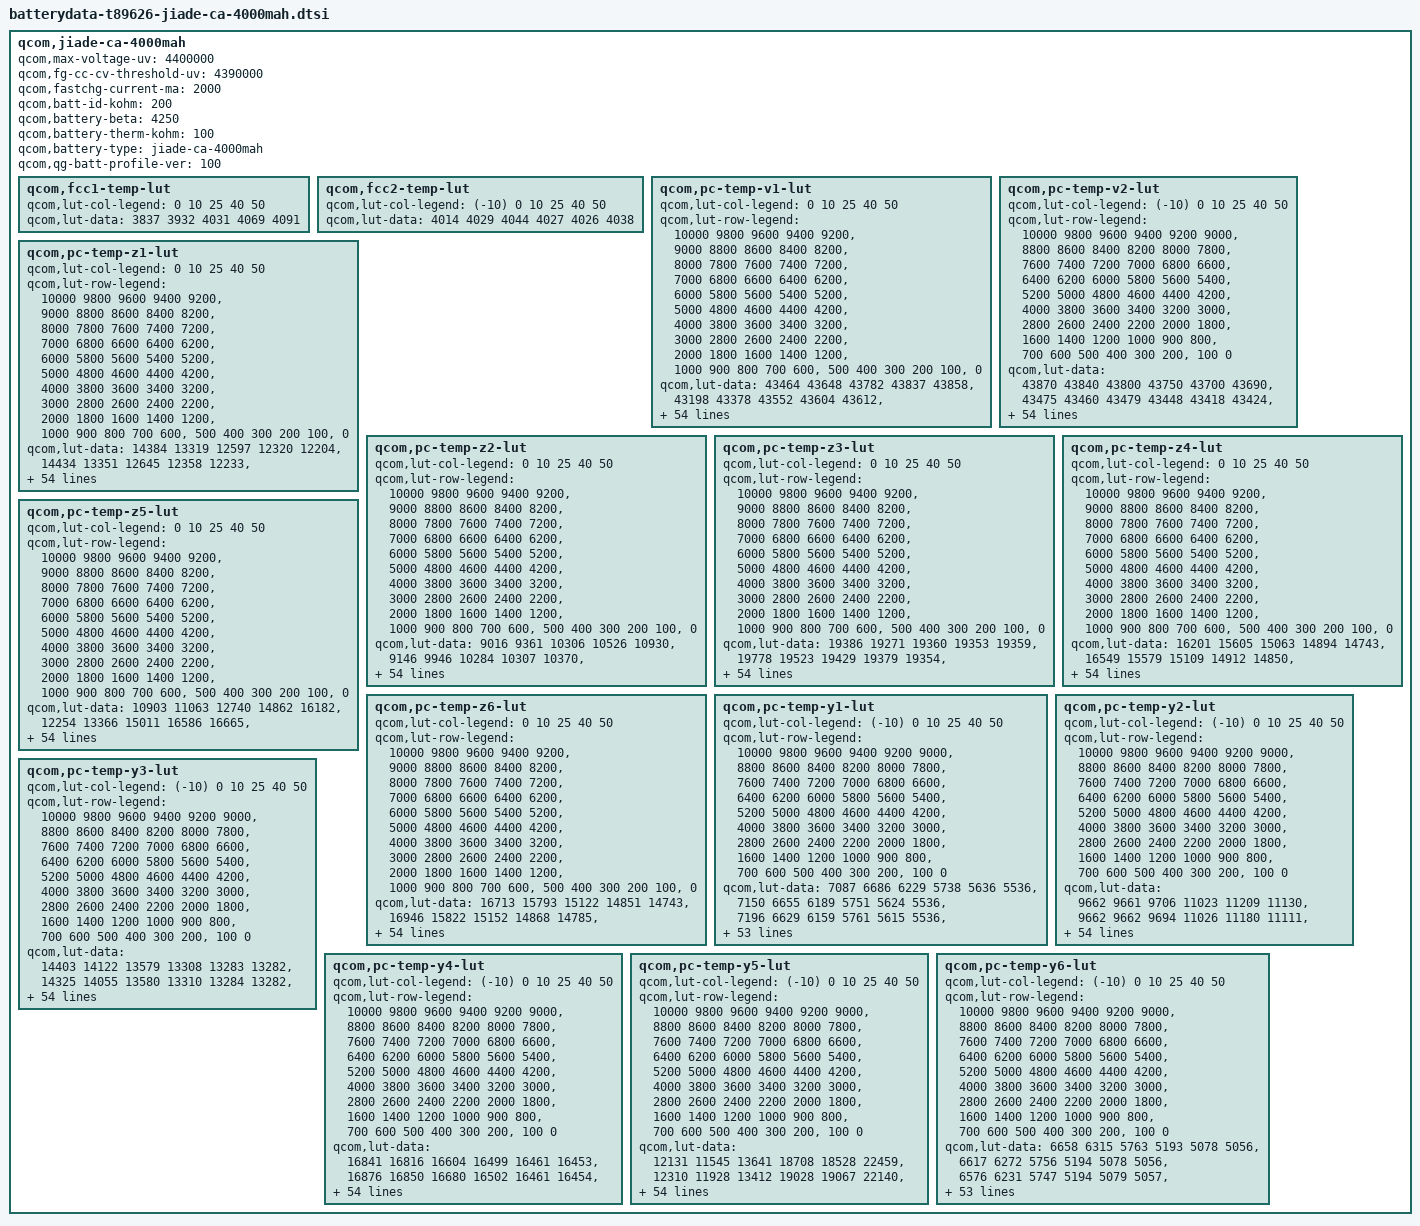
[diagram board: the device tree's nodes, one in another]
qcom,jiade-ca-4000mah {
    /* 3763683_Wingtech_T89626_JD_4000mAh_FG_averaged_MasterSlave_Jan8th2019 */
    qcom,max-voltage-uv = <4400000>;
    qcom,fg-cc-cv-threshold-uv = <4390000>;
    qcom,fastchg-current-ma = <2000>;
    qcom,batt-id-kohm = <200>;
    qcom,battery-beta = <4250>;
    qcom,battery-therm-kohm = <100>;
    qcom,battery-type = "jiade-ca-4000mah";
    qcom,qg-batt-profile-ver = <100>;

	qcom,fcc1-temp-lut {
		qcom,lut-col-legend = <0 10 25 40 50>;
		qcom,lut-data = <3837 3932 4031 4069 4091>;
	};

	qcom,fcc2-temp-lut {
		qcom,lut-col-legend = <(-10) 0 10 25 40 50>;
		qcom,lut-data = <4014 4029 4044 4027 4026 4038>;
	};

	qcom,pc-temp-v1-lut {
		qcom,lut-col-legend = <0 10 25 40 50>;
		qcom,lut-row-legend = <10000 9800 9600 9400 9200>,
			<9000 8800 8600 8400 8200>,
			<8000 7800 7600 7400 7200>,
			<7000 6800 6600 6400 6200>,
			<6000 5800 5600 5400 5200>,
			<5000 4800 4600 4400 4200>,
			<4000 3800 3600 3400 3200>,
			<3000 2800 2600 2400 2200>,
			<2000 1800 1600 1400 1200>,
			<1000 900 800 700 600>,
			<500 400 300 200 100>,
			<0>;
		qcom,lut-data = <43464 43648 43782 43837 43858>,
			<43198 43378 43552 43604 43612>,
			<42939 43121 43306 43371 43382>,
			<42690 42879 43062 43137 43152>,
			<42454 42645 42824 42903 42921>,
			<42227 42410 42588 42667 42686>,
			<42009 42179 42355 42433 42453>,
			<41801 41956 42123 42200 42222>,
			<41602 41740 41895 41971 41993>,
			<41409 41532 41670 41745 41767>,
			<41227 41338 41451 41522 41542>,
			<41032 41156 41247 41303 41322>,
			<40806 40960 41056 41087 41104>,
			<40566 40728 40857 40878 40892>,
			<40338 40486 40633 40674 40687>,
			<40111 40268 40413 40476 40490>,
			<39913 40062 40221 40289 40300>,
			<39762 39885 40045 40113 40118>,
			<39636 39745 39882 39944 39943>,
			<39513 39620 39743 39784 39780>,
			<39389 39487 39596 39627 39625>,
			<39271 39347 39384 39434 39440>,
			<39157 39202 39118 39172 39190>,
			<39048 39045 38916 38943 38961>,
			<38944 38883 38775 38805 38817>,
			<38846 38731 38663 38698 38702>,
			<38752 38579 38572 38594 38592>,
			<38666 38458 38497 38494 38485>,
			<38584 38387 38425 38404 38388>,
			<38509 38334 38355 38321 38303>,
			<38439 38287 38291 38248 38227>,
			<38373 38244 38230 38179 38156>,
			<38317 38205 38175 38118 38091>,
			<38269 38168 38125 38060 38029>,
			<38226 38135 38083 38011 37972>,
			<38183 38105 38043 37963 37916>,
			<38140 38082 38003 37911 37856>,
			<38093 38054 37962 37856 37794>,
			<38035 38006 37902 37790 37720>,
			<37966 37925 37809 37703 37629>,
			<37881 37829 37701 37601 37526>,
			<37765 37711 37588 37492 37414>,
			<37633 37575 37460 37367 37288>,
			<37482 37418 37302 37217 37131>,
			<37337 37275 37163 37076 36998>,
			<37231 37171 37068 36981 36917>,
			<37194 37135 37046 36951 36887>,
			<37164 37111 37026 36931 36867>,
			<37136 37085 37005 36912 36849>,
			<37082 37038 36958 36865 36782>,
			<36879 36812 36709 36637 36504>,
			<36440 36376 36276 36200 36065>,
			<35871 35803 35700 35612 35490>,
			<35093 35019 34918 34805 34705>,
			<33855 33776 33672 33521 33485>,
			<30000 30000 30000 30000 30000>;
	};

	qcom,pc-temp-v2-lut {
		qcom,lut-col-legend = <(-10) 0 10 25 40 50>;
		qcom,lut-row-legend = <10000 9800 9600 9400 9200 9000>,
			<8800 8600 8400 8200 8000 7800>,
			<7600 7400 7200 7000 6800 6600>,
			<6400 6200 6000 5800 5600 5400>,
			<5200 5000 4800 4600 4400 4200>,
			<4000 3800 3600 3400 3200 3000>,
			<2800 2600 2400 2200 2000 1800>,
			<1600 1400 1200 1000 900 800>,
			<700 600 500 400 300 200>,
			<100 0>;
		qcom,lut-data = <43870 43840 43800 43750 43700 43690>,
			<43475 43460 43479 43448 43418 43424>,
			<43116 43115 43174 43164 43151 43168>,
			<42800 42810 42890 42903 42899 42922>,
			<42520 42540 42622 42662 42663 42687>,
			<42258 42284 42367 42426 42431 42455>,
			<42007 42033 42124 42193 42199 42223>,
			<41769 41792 41890 41962 41970 41993>,
			<41539 41560 41661 41735 41743 41766>,
			<41314 41332 41436 41512 41519 41541>,
			<41116 41139 41223 41292 41298 41319>,
			<40973 41008 41031 41077 41082 41103>,
			<40833 40882 40842 40866 40871 40890>,
			<40579 40647 40631 40659 40668 40684>,
			<40136 40257 40401 40454 40470 40482>,
			<39769 39924 40171 40257 40280 40289>,
			<39558 39703 39942 40067 40097 40105>,
			<39390 39516 39717 39886 39921 39927>,
			<39223 39333 39504 39724 39752 39757>,
			<39066 39162 39298 39580 39594 39595>,
			<38918 38998 39104 39410 39415 39413>,
			<38775 38837 38917 39168 39182 39185>,
			<38645 38685 38746 38917 38945 38958>,
			<38533 38552 38596 38739 38768 38783>,
			<38436 38432 38460 38595 38621 38632>,
			<38349 38329 38346 38471 38495 38503>,
			<38272 38244 38248 38362 38385 38392>,
			<38202 38171 38165 38264 38287 38293>,
			<38133 38102 38096 38174 38197 38200>,
			<38066 38039 38036 38091 38114 38115>,
			<38005 37982 37980 38016 38039 38038>,
			<37947 37929 37928 37945 37973 37970>,
			<37894 37878 37878 37882 37911 37904>,
			<37847 37827 37829 37826 37844 37835>,
			<37806 37777 37783 37777 37776 37764>,
			<37764 37724 37734 37726 37700 37679>,
			<37721 37670 37684 37674 37611 37569>,
			<37676 37613 37628 37616 37520 37460>,
			<37615 37547 37563 37545 37439 37372>,
			<37538 37475 37490 37461 37363 37292>,
			<37450 37391 37407 37372 37280 37209>,
			<37344 37286 37306 37277 37189 37124>,
			<37224 37182 37188 37165 37083 37017>,
			<37085 37088 37051 37029 36953 36882>,
			<36964 37004 36926 36901 36840 36775>,
			<36898 36921 36840 36836 36789 36736>,
			<36875 36881 36813 36814 36775 36726>,
			<36854 36828 36777 36792 36758 36708>,
			<36819 36752 36732 36762 36727 36671>,
			<36736 36618 36628 36682 36637 36547>,
			<36478 36362 36384 36423 36347 36179>,
			<35992 35942 35926 35951 35860 35668>,
			<35349 35342 35285 35331 35230 35001>,
			<34449 34469 34375 34469 34378 34072>,
			<33161 33014 32955 33187 33121 32730>,
			<27680 28140 27790 27698 27500 28428>;
	};

	qcom,pc-temp-z1-lut {
		qcom,lut-col-legend = <0 10 25 40 50>;
		qcom,lut-row-legend = <10000 9800 9600 9400 9200>,
			<9000 8800 8600 8400 8200>,
			<8000 7800 7600 7400 7200>,
			<7000 6800 6600 6400 6200>,
			<6000 5800 5600 5400 5200>,
			<5000 4800 4600 4400 4200>,
			<4000 3800 3600 3400 3200>,
			<3000 2800 2600 2400 2200>,
			<2000 1800 1600 1400 1200>,
			<1000 900 800 700 600>,
			<500 400 300 200 100>,
			<0>;
		qcom,lut-data = <14384 13319 12597 12320 12204>,
			<14434 13351 12645 12358 12233>,
			<14430 13359 12659 12349 12233>,
			<14424 13352 12664 12336 12225>,
			<14416 13344 12662 12328 12216>,
			<14404 13341 12658 12321 12205>,
			<14386 13340 12649 12318 12199>,
			<14347 13340 12631 12320 12198>,
			<14314 13348 12622 12321 12197>,
			<14312 13358 12621 12320 12197>,
			<14315 13356 12621 12316 12196>,
			<14317 13347 12622 12313 12194>,
			<14271 13337 12627 12310 12193>,
			<14204 13325 12628 12308 12193>,
			<14190 13314 12624 12310 12193>,
			<14196 13314 12618 12316 12193>,
			<14201 13317 12622 12317 12193>,
			<14180 13323 12634 12315 12194>,
			<14132 13335 12639 12312 12195>,
			<14109 13353 12633 12313 12197>,
			<14106 13365 12627 12315 12199>,
			<14104 13375 12628 12317 12202>,
			<14098 13379 12631 12318 12205>,
			<14088 13372 12634 12320 12207>,
			<14083 13361 12636 12324 12209>,
			<14083 13361 12638 12330 12209>,
			<14086 13383 12646 12333 12211>,
			<14090 13400 12658 12335 12215>,
			<14100 13395 12663 12337 12220>,
			<14113 13383 12663 12344 12223>,
			<14127 13380 12664 12352 12227>,
			<14142 13387 12668 12354 12231>,
			<14164 13398 12677 12353 12238>,
			<14211 13415 12685 12353 12245>,
			<14253 13438 12695 12356 12250>,
			<14249 13445 12700 12362 12255>,
			<14217 13436 12695 12367 12260>,
			<14197 13426 12685 12375 12263>,
			<14232 13426 12685 12379 12267>,
			<14287 13431 12700 12380 12270>,
			<14298 13437 12713 12381 12273>,
			<14277 13441 12716 12390 12278>,
			<14275 13451 12717 12406 12285>,
			<14318 13501 12706 12407 12291>,
			<14288 13493 12703 12406 12291>,
			<14285 13452 12720 12395 12291>,
			<14343 13484 12702 12395 12290>,
			<14283 13468 12700 12408 12292>,
			<14233 13469 12713 12401 12292>,
			<14248 13494 12717 12401 12305>,
			<14252 13473 12735 12414 12314>,
			<14275 13527 12754 12417 12314>,
			<14301 13551 12771 12428 12326>,
			<14379 13606 12782 12458 12339>,
			<14379 13606 12782 12458 12339>,
			<14379 13606 12782 12458 12339>;
	};

	qcom,pc-temp-z2-lut {
		qcom,lut-col-legend = <0 10 25 40 50>;
		qcom,lut-row-legend = <10000 9800 9600 9400 9200>,
			<9000 8800 8600 8400 8200>,
			<8000 7800 7600 7400 7200>,
			<7000 6800 6600 6400 6200>,
			<6000 5800 5600 5400 5200>,
			<5000 4800 4600 4400 4200>,
			<4000 3800 3600 3400 3200>,
			<3000 2800 2600 2400 2200>,
			<2000 1800 1600 1400 1200>,
			<1000 900 800 700 600>,
			<500 400 300 200 100>,
			<0>;
		qcom,lut-data = <9016 9361 10306 10526 10930>,
			<9146 9946 10284 10307 10370>,
			<9628 10127 10357 10367 10373>,
			<9993 10126 10396 10454 10411>,
			<10014 10123 10387 10460 10419>,
			<10021 10114 10368 10425 10397>,
			<10029 10093 10349 10401 10371>,
			<10042 10079 10326 10394 10355>,
			<10051 10071 10310 10389 10339>,
			<10049 10067 10303 10382 10313>,
			<10038 10069 10298 10373 10268>,
			<10025 10077 10302 10370 10247>,
			<10004 10081 10318 10375 10262>,
			<9984 10075 10332 10385 10282>,
			<9980 10067 10343 10400 10284>,
			<9981 10070 10352 10420 10282>,
			<9983 10091 10360 10425 10281>,
			<9994 10120 10365 10412 10298>,
			<10023 10175 10375 10399 10321>,
			<10053 10233 10404 10403 10335>,
			<10094 10241 10429 10414 10346>,
			<10127 10228 10421 10430 10365>,
			<10078 10219 10393 10457 10409>,
			<9885 10222 10379 10474 10441>,
			<9763 10229 10375 10462 10419>,
			<9751 10230 10373 10438 10375>,
			<9745 10225 10374 10429 10365>,
			<9735 10220 10376 10427 10370>,
			<9721 10226 10376 10423 10373>,
			<9712 10239 10370 10392 10332>,
			<9712 10250 10365 10352 10264>,
			<9714 10256 10369 10346 10240>,
			<9707 10262 10382 10351 10229>,
			<9571 10275 10390 10360 10226>,
			<9416 10291 10394 10376 10248>,
			<9410 10294 10399 10398 10289>,
			<9457 10246 10407 10419 10332>,
			<9485 10197 10419 10440 10385>,
			<9484 10214 10435 10461 10408>,
			<9481 10296 10461 10488 10411>,
			<9480 10402 10477 10507 10414>,
			<9480 10595 10474 10490 10419>,
			<9477 10691 10469 10450 10427>,
			<9455 10388 10472 10464 10448>,
			<9419 10928 10516 10489 10449>,
			<9411 11215 10559 10503 10436>,
			<9418 10701 10583 10502 10440>,
			<9408 11307 10621 10516 10435>,
			<9411 10609 10804 10507 10487>,
			<9403 10768 11191 10621 10552>,
			<9375 11064 10733 10554 10367>,
			<9360 10423 10751 10462 10268>,
			<9348 10282 10649 10381 10249>,
			<9309 9997 10611 10321 10194>,
			<9309 9997 10611 10321 10194>,
			<9309 9997 10611 10321 10194>;
	};

	qcom,pc-temp-z3-lut {
		qcom,lut-col-legend = <0 10 25 40 50>;
		qcom,lut-row-legend = <10000 9800 9600 9400 9200>,
			<9000 8800 8600 8400 8200>,
			<8000 7800 7600 7400 7200>,
			<7000 6800 6600 6400 6200>,
			<6000 5800 5600 5400 5200>,
			<5000 4800 4600 4400 4200>,
			<4000 3800 3600 3400 3200>,
			<3000 2800 2600 2400 2200>,
			<2000 1800 1600 1400 1200>,
			<1000 900 800 700 600>,
			<500 400 300 200 100>,
			<0>;
		qcom,lut-data = <19386 19271 19360 19353 19359>,
			<19778 19523 19429 19379 19354>,
			<19843 19625 19467 19392 19367>,
			<19865 19650 19482 19399 19376>,
			<19865 19663 19487 19405 19382>,
			<19864 19670 19489 19409 19387>,
			<19861 19675 19490 19411 19390>,
			<19839 19677 19490 19413 19390>,
			<19814 19669 19491 19413 19389>,
			<19804 19657 19491 19412 19387>,
			<19797 19641 19490 19405 19381>,
			<19795 19619 19487 19401 19377>,
			<19803 19610 19476 19399 19375>,
			<19816 19615 19468 19397 19373>,
			<19816 19622 19464 19396 19371>,
			<19802 19622 19461 19394 19368>,
			<19779 19616 19458 19392 19365>,
			<19743 19608 19455 19388 19364>,
			<19692 19574 19452 19384 19363>,
			<19648 19532 19445 19381 19360>,
			<19615 19528 19439 19379 19354>,
			<19582 19548 19445 19380 19353>,
			<19536 19571 19462 19386 19360>,
			<19475 19592 19468 19392 19365>,
			<19443 19610 19466 19387 19364>,
			<19439 19614 19462 19380 19363>,
			<19436 19614 19460 19381 19365>,
			<19434 19614 19458 19397 19385>,
			<19431 19611 19457 19408 19399>,
			<19428 19603 19458 19407 19395>,
			<19427 19595 19458 19405 19388>,
			<19427 19587 19460 19403 19383>,
			<19422 19577 19462 19400 19378>,
			<19359 19569 19462 19396 19373>,
			<19286 19561 19459 19391 19368>,
			<19274 19539 19455 19386 19363>,
			<19272 19406 19450 19383 19360>,
			<19271 19274 19445 19382 19358>,
			<19271 19262 19444 19380 19357>,
			<19271 19262 19445 19379 19357>,
			<19271 19261 19446 19378 19357>,
			<19270 19260 19442 19374 19355>,
			<19270 19260 19436 19369 19353>,
			<19271 19261 19435 19369 19358>,
			<19272 19259 19424 19366 19358>,
			<19272 19258 19413 19356 19342>,
			<19272 19260 19388 19355 19340>,
			<19273 19258 19357 19351 19337>,
			<19272 19260 19334 19353 19327>,
			<19272 19259 19268 19337 19326>,
			<19274 19259 19342 19348 19351>,
			<19275 19260 19334 19358 19356>,
			<19275 19261 19338 19362 19356>,
			<19278 19263 19272 19361 19356>,
			<19278 19263 19272 19361 19356>,
			<19278 19263 19272 19361 19356>;
	};

	qcom,pc-temp-z4-lut {
		qcom,lut-col-legend = <0 10 25 40 50>;
		qcom,lut-row-legend = <10000 9800 9600 9400 9200>,
			<9000 8800 8600 8400 8200>,
			<8000 7800 7600 7400 7200>,
			<7000 6800 6600 6400 6200>,
			<6000 5800 5600 5400 5200>,
			<5000 4800 4600 4400 4200>,
			<4000 3800 3600 3400 3200>,
			<3000 2800 2600 2400 2200>,
			<2000 1800 1600 1400 1200>,
			<1000 900 800 700 600>,
			<500 400 300 200 100>,
			<0>;
		qcom,lut-data = <16201 15605 15063 14894 14743>,
			<16549 15579 15109 14912 14850>,
			<16347 15519 15055 14895 14850>,
			<16113 15384 14993 14862 14830>,
			<15948 15233 14931 14833 14811>,
			<15797 15132 14872 14804 14790>,
			<15666 15050 14829 14778 14770>,
			<15549 14987 14796 14756 14753>,
			<15448 14937 14769 14737 14737>,
			<15366 14899 14745 14722 14725>,
			<15297 14874 14726 14709 14715>,
			<15237 14856 14712 14700 14707>,
			<15181 14837 14700 14693 14700>,
			<15134 14811 14695 14687 14694>,
			<15108 14785 14694 14681 14690>,
			<15090 14767 14694 14676 14686>,
			<15081 14751 14690 14672 14682>,
			<15085 14744 14682 14667 14676>,
			<15097 14758 14675 14664 14672>,
			<15109 14778 14670 14662 14670>,
			<15119 14775 14667 14660 14668>,
			<15131 14742 14693 14668 14673>,
			<15158 14719 14763 14739 14736>,
			<15208 14719 14792 14795 14789>,
			<15234 14721 14795 14793 14787>,
			<15225 14728 14797 14785 14775>,
			<15206 14759 14787 14771 14759>,
			<15190 14783 14762 14739 14726>,
			<15178 14777 14741 14712 14700>,
			<15165 14760 14725 14698 14691>,
			<15148 14745 14711 14688 14685>,
			<15130 14734 14699 14681 14679>,
			<15126 14725 14689 14675 14673>,
			<15174 14718 14683 14672 14670>,
			<15229 14713 14680 14671 14669>,
			<15231 14718 14678 14670 14668>,
			<15212 14849 14676 14670 14668>,
			<15192 14987 14674 14670 14670>,
			<15177 14997 14674 14670 14671>,
			<15162 14992 14677 14674 14675>,
			<15150 14987 14678 14677 14679>,
			<15141 14985 14676 14676 14676>,
			<15129 14981 14672 14673 14669>,
			<15108 14974 14670 14673 14669>,
			<15014 14931 14665 14672 14666>,
			<14990 14902 14652 14658 14655>,
			<14986 14898 14669 14652 14650>,
			<14979 14895 14696 14644 14639>,
			<14978 14888 14718 14631 14633>,
			<14975 14886 14790 14646 14634>,
			<14976 14896 14717 14651 14637>,
			<14999 14910 14733 14651 14641>,
			<15017 14919 14733 14651 14646>,
			<15040 14933 14811 14657 14651>,
			<15040 14933 14811 14657 14651>,
			<15040 14933 14811 14657 14651>;
	};

	qcom,pc-temp-z5-lut {
		qcom,lut-col-legend = <0 10 25 40 50>;
		qcom,lut-row-legend = <10000 9800 9600 9400 9200>,
			<9000 8800 8600 8400 8200>,
			<8000 7800 7600 7400 7200>,
			<7000 6800 6600 6400 6200>,
			<6000 5800 5600 5400 5200>,
			<5000 4800 4600 4400 4200>,
			<4000 3800 3600 3400 3200>,
			<3000 2800 2600 2400 2200>,
			<2000 1800 1600 1400 1200>,
			<1000 900 800 700 600>,
			<500 400 300 200 100>,
			<0>;
		qcom,lut-data = <10903 11063 12740 14862 16182>,
			<12254 13366 15011 16586 16665>,
			<13107 14624 16692 17706 17766>,
			<13710 15179 17896 18525 18717>,
			<14166 15617 18660 19318 19604>,
			<14518 16235 19295 20034 20460>,
			<14656 16915 20080 20809 21174>,
			<14688 17299 20958 21839 21745>,
			<14715 17487 22004 22809 22199>,
			<14796 17591 23691 23316 22438>,
			<14971 17491 25185 23623 22555>,
			<15193 17128 25497 24081 22744>,
			<15569 16959 25583 25009 23497>,
			<15954 18067 25751 26208 24525>,
			<16020 19895 26446 27694 25145>,
			<15913 21321 27323 29403 25569>,
			<15724 22703 27929 29917 26270>,
			<15174 23326 28447 29778 28395>,
			<14170 20793 28594 29651 30280>,
			<13457 17020 28211 30147 30021>,
			<13059 16647 27811 31236 28867>,
			<12725 19358 32560 31556 27884>,
			<12322 23628 45391 31562 27252>,
			<11867 33851 49746 31564 26409>,
			<11655 46832 41347 27758 23498>,
			<11671 49688 31957 20924 19217>,
			<11702 49436 28547 19756 18824>,
			<11728 48955 26323 22128 23366>,
			<11750 46568 25822 24805 27209>,
			<11775 41636 26457 26749 28103>,
			<11819 37626 27640 28649 28703>,
			<11874 34496 30470 30975 29886>,
			<11875 31803 35269 33866 31880>,
			<11486 29832 38339 35343 33079>,
			<11045 28244 40362 35606 33419>,
			<10990 25563 41368 35738 33599>,
			<10991 18192 39720 35636 33499>,
			<10993 11670 36596 35112 32970>,
			<10999 11170 36136 34369 32193>,
			<11009 11194 38236 33138 30608>,
			<11021 11205 39837 31374 28708>,
			<11037 11202 36711 28456 26996>,
			<11062 11200 32577 25127 25694>,
			<11115 11225 32457 24796 28510>,
			<11375 11360 30696 24188 29055>,
			<11413 11406 29984 22500 21848>,
			<11394 11393 20320 22804 21689>,
			<11393 11366 15577 22615 22212>,
			<11372 11367 13776 25538 20860>,
			<11393 11385 11575 19439 19460>,
			<11420 11417 14294 19548 26141>,
			<11404 11341 13493 20711 25454>,
			<11317 11288 13508 20920 22670>,
			<11235 11193 11471 19385 20552>,
			<11235 11193 11471 19385 20552>,
			<11235 11193 11471 19385 20552>;
	};

	qcom,pc-temp-z6-lut {
		qcom,lut-col-legend = <0 10 25 40 50>;
		qcom,lut-row-legend = <10000 9800 9600 9400 9200>,
			<9000 8800 8600 8400 8200>,
			<8000 7800 7600 7400 7200>,
			<7000 6800 6600 6400 6200>,
			<6000 5800 5600 5400 5200>,
			<5000 4800 4600 4400 4200>,
			<4000 3800 3600 3400 3200>,
			<3000 2800 2600 2400 2200>,
			<2000 1800 1600 1400 1200>,
			<1000 900 800 700 600>,
			<500 400 300 200 100>,
			<0>;
		qcom,lut-data = <16713 15793 15122 14851 14743>,
			<16946 15822 15152 14868 14785>,
			<16821 15819 15129 14861 14788>,
			<16673 15738 15100 14848 14784>,
			<16566 15630 15064 14835 14779>,
			<16467 15560 15026 14821 14770>,
			<16370 15502 14998 14808 14762>,
			<16270 15452 14976 14798 14754>,
			<16181 15409 14957 14788 14746>,
			<16114 15372 14942 14778 14739>,
			<16061 15340 14929 14768 14731>,
			<16012 15312 14917 14761 14725>,
			<15964 15286 14905 14757 14720>,
			<15918 15258 14896 14753 14717>,
			<15877 15233 14889 14750 14713>,
			<15840 15218 14883 14746 14710>,
			<15809 15207 14879 14743 14707>,
			<15785 15199 14876 14739 14704>,
			<15765 15191 14873 14736 14702>,
			<15746 15185 14869 14734 14699>,
			<15729 15184 14867 14732 14696>,
			<15714 15186 14882 14736 14698>,
			<15698 15189 14923 14771 14728>,
			<15681 15197 14940 14799 14755>,
			<15668 15211 14941 14796 14754>,
			<15658 15225 14942 14791 14749>,
			<15651 15242 14938 14786 14745>,
			<15646 15252 14929 14781 14742>,
			<15644 15250 14922 14777 14738>,
			<15642 15242 14917 14773 14734>,
			<15638 15235 14914 14768 14728>,
			<15633 15229 14913 14765 14723>,
			<15631 15223 14912 14762 14719>,
			<15631 15218 14911 14759 14716>,
			<15631 15214 14910 14757 14713>,
			<15630 15211 14910 14756 14711>,
			<15627 15208 14910 14756 14711>,
			<15625 15206 14910 14756 14711>,
			<15628 15207 14912 14757 14712>,
			<15634 15209 14918 14760 14715>,
			<15635 15211 14923 14763 14718>,
			<15635 15216 14923 14762 14717>,
			<15636 15222 14922 14759 14714>,
			<15640 15227 14924 14760 14718>,
			<15609 15219 14921 14760 14717>,
			<15603 15209 14915 14750 14705>,
			<15600 15208 14910 14748 14701>,
			<15596 15209 14907 14743 14696>,
			<15596 15204 14907 14739 14689>,
			<15603 15211 14908 14739 14689>,
			<15613 15221 14919 14750 14706>,
			<15630 15237 14925 14757 14713>,
			<15654 15251 14933 14763 14718>,
			<15682 15272 14943 14770 14724>,
			<15682 15272 14943 14770 14724>,
			<15682 15272 14943 14770 14724>;
	};

	qcom,pc-temp-y1-lut {
		qcom,lut-col-legend = <(-10) 0 10 25 40 50>;
		qcom,lut-row-legend = <10000 9800 9600 9400 9200 9000>,
			<8800 8600 8400 8200 8000 7800>,
			<7600 7400 7200 7000 6800 6600>,
			<6400 6200 6000 5800 5600 5400>,
			<5200 5000 4800 4600 4400 4200>,
			<4000 3800 3600 3400 3200 3000>,
			<2800 2600 2400 2200 2000 1800>,
			<1600 1400 1200 1000 900 800>,
			<700 600 500 400 300 200>,
			<100 0>;
		qcom,lut-data = <7087 6686 6229 5738 5636 5536>,
			<7150 6655 6189 5751 5624 5536>,
			<7196 6629 6159 5761 5615 5536>,
			<7225 6609 6137 5768 5609 5536>,
			<7242 6596 6125 5773 5605 5536>,
			<7247 6592 6121 5775 5603 5536>,
			<7231 6599 6132 5771 5607 5535>,
			<7206 6610 6147 5767 5611 5533>,
			<7201 6608 6147 5767 5611 5531>,
			<7199 6589 6139 5770 5606 5530>,
			<7199 6578 6132 5772 5601 5529>,
			<7236 6593 6129 5769 5598 5527>,
			<7295 6616 6127 5766 5595 5526>,
			<7326 6626 6131 5767 5595 5524>,
			<7346 6633 6148 5775 5597 5521>,
			<7353 6635 6157 5783 5600 5519>,
			<7331 6625 6158 5789 5601 5519>,
			<7296 6612 6158 5794 5602 5518>,
			<7278 6614 6163 5792 5601 5518>,
			<7266 6627 6173 5784 5596 5517>,
			<7259 6632 6177 5780 5594 5517>,
			<7257 6623 6171 5783 5594 5518>,
			<7255 6613 6163 5786 5595 5520>,
			<7248 6615 6156 5786 5598 5520>,
			<7226 6627 6151 5784 5604 5521>,
			<7190 6636 6149 5783 5606 5522>,
			<7060 6639 6151 5786 5606 5523>,
			<6875 6643 6154 5790 5606 5525>,
			<6741 6649 6161 5790 5608 5527>,
			<6628 6659 6172 5789 5614 5530>,
			<6537 6663 6173 5789 5619 5533>,
			<6467 6662 6158 5797 5623 5536>,
			<6407 6660 6144 5806 5626 5539>,
			<6344 6655 6145 5807 5626 5542>,
			<6281 6643 6148 5806 5625 5547>,
			<6221 6630 6151 5806 5625 5548>,
			<6158 6613 6155 5806 5625 5548>,
			<6104 6599 6158 5806 5626 5548>,
			<6070 6597 6157 5804 5627 5550>,
			<6047 6595 6154 5798 5630 5554>,
			<6027 6597 6149 5796 5633 5556>,
			<6012 6619 6140 5798 5638 5557>,
			<5995 6628 6147 5798 5640 5560>,
			<5972 6620 6175 5793 5635 5567>,
			<5958 6614 6167 5804 5640 5569>,
			<5940 6679 6160 5813 5641 5573>,
			<5938 6691 6165 5809 5639 5571>,
			<5939 6682 6202 5813 5642 5569>,
			<5934 6660 6192 5806 5642 5569>,
			<5917 6662 6193 5804 5642 5567>,
			<5920 6696 6183 5824 5645 5574>,
			<5926 6714 6227 5838 5654 5583>,
			<5920 6759 6218 5828 5662 5584>,
			<5946 6797 6241 5841 5675 5596>,
			<5946 6797 6241 5841 5675 5596>,
			<5946 6797 6241 5841 5675 5596>;
	};

	qcom,pc-temp-y2-lut {
		qcom,lut-col-legend = <(-10) 0 10 25 40 50>;
		qcom,lut-row-legend = <10000 9800 9600 9400 9200 9000>,
			<8800 8600 8400 8200 8000 7800>,
			<7600 7400 7200 7000 6800 6600>,
			<6400 6200 6000 5800 5600 5400>,
			<5200 5000 4800 4600 4400 4200>,
			<4000 3800 3600 3400 3200 3000>,
			<2800 2600 2400 2200 2000 1800>,
			<1600 1400 1200 1000 900 800>,
			<700 600 500 400 300 200>,
			<100 0>;
		qcom,lut-data = <9662 9661 9706 11023 11209 11130>,
			<9662 9662 9694 11026 11180 11111>,
			<9662 9663 9688 11023 11149 11092>,
			<9662 9665 9688 11015 11119 11073>,
			<9662 9666 9694 11003 11094 11054>,
			<9663 9666 9705 10988 11077 11035>,
			<9663 9667 9843 10967 11068 11016>,
			<9664 9667 10064 10943 11061 10997>,
			<9664 9668 10204 10928 11047 10978>,
			<9664 9668 10313 10916 11019 10958>,
			<9664 9669 10376 10904 11000 10949>,
			<9664 9670 10398 10883 10994 10953>,
			<9664 9671 10417 10864 10990 10957>,
			<9664 9670 10476 10870 10986 10953>,
			<9664 9669 10590 10910 10983 10935>,
			<9664 9668 10628 10952 10982 10924>,
			<9664 9668 10256 10984 11011 10921>,
			<9664 9668 9825 11017 11063 10920>,
			<9664 9668 9760 11067 11118 10969>,
			<9664 9668 9744 11136 11185 11124>,
			<9664 9668 9729 11165 11213 11190>,
			<9664 9668 9711 11137 11198 11150>,
			<9664 9667 9698 11105 11180 11106>,
			<9664 9667 9694 11104 11181 11104>,
			<9664 9667 9692 11117 11193 11107>,
			<9665 9667 9692 11132 11200 11112>,
			<9667 9666 9693 11154 11201 11126>,
			<9671 9666 9694 11172 11203 11144>,
			<9677 9665 9691 11172 11210 11166>,
			<9686 9665 9685 11164 11228 11192>,
			<9701 9665 9681 11155 11243 11199>,
			<9741 9664 9679 11145 11256 11197>,
			<9817 9664 9678 11135 11265 11193>,
			<10039 9663 9675 11127 11268 11188>,
			<10547 9663 9673 11119 11270 11179>,
			<10797 9663 9671 11106 11268 11167>,
			<10813 9663 9669 11080 11216 11143>,
			<10820 9662 9668 11044 11156 11122>,
			<10819 9662 9667 10997 11132 11115>,
			<10809 9661 9665 10937 11117 11110>,
			<10797 9661 9664 10884 11114 11110>,
			<10783 9661 9663 10848 11132 11115>,
			<10759 9660 9662 10758 11136 11115>,
			<10683 9660 9661 10463 11085 11094>,
			<10606 9660 9661 10401 10975 10999>,
			<10613 9659 9660 10371 10950 10905>,
			<10589 9659 9660 10257 10988 10975>,
			<10612 9659 9659 10232 11007 10981>,
			<10645 9658 9659 10475 11017 10983>,
			<10659 9658 9659 10547 11034 10986>,
			<10612 9657 9658 10261 10978 10869>,
			<10491 9657 9658 9906 10899 10842>,
			<10374 9656 9657 9723 10818 10754>,
			<10261 9654 9656 9701 10803 10763>,
			<10261 9654 9656 9701 10803 10763>,
			<10261 9654 9656 9701 10803 10763>;
	};

	qcom,pc-temp-y3-lut {
		qcom,lut-col-legend = <(-10) 0 10 25 40 50>;
		qcom,lut-row-legend = <10000 9800 9600 9400 9200 9000>,
			<8800 8600 8400 8200 8000 7800>,
			<7600 7400 7200 7000 6800 6600>,
			<6400 6200 6000 5800 5600 5400>,
			<5200 5000 4800 4600 4400 4200>,
			<4000 3800 3600 3400 3200 3000>,
			<2800 2600 2400 2200 2000 1800>,
			<1600 1400 1200 1000 900 800>,
			<700 600 500 400 300 200>,
			<100 0>;
		qcom,lut-data = <14403 14122 13579 13308 13283 13282>,
			<14325 14055 13580 13310 13284 13282>,
			<14250 13991 13574 13311 13286 13281>,
			<14181 13932 13562 13313 13287 13282>,
			<14119 13880 13547 13314 13288 13282>,
			<14066 13836 13528 13315 13289 13282>,
			<14025 13803 13497 13317 13290 13283>,
			<13988 13773 13468 13318 13290 13284>,
			<13938 13733 13466 13319 13290 13284>,
			<13872 13682 13475 13320 13290 13285>,
			<13840 13649 13479 13320 13290 13285>,
			<13850 13637 13444 13319 13291 13286>,
			<13865 13628 13400 13318 13292 13287>,
			<13856 13613 13398 13319 13293 13287>,
			<13806 13593 13410 13321 13294 13286>,
			<13774 13575 13415 13323 13295 13286>,
			<13770 13560 13412 13320 13296 13287>,
			<13768 13548 13408 13317 13297 13289>,
			<13768 13544 13402 13317 13297 13289>,
			<13770 13542 13393 13318 13296 13290>,
			<13771 13540 13384 13319 13295 13290>,
			<13770 13536 13373 13314 13292 13287>,
			<13766 13532 13362 13308 13289 13283>,
			<13759 13531 13351 13306 13288 13282>,
			<13744 13530 13341 13304 13287 13281>,
			<13718 13530 13333 13303 13286 13281>,
			<13628 13542 13326 13302 13286 13281>,
			<13512 13559 13322 13301 13285 13281>,
			<13452 13573 13329 13301 13285 13281>,
			<13413 13586 13349 13301 13284 13280>,
			<13386 13603 13364 13301 13284 13280>,
			<13365 13629 13374 13301 13285 13280>,
			<13350 13657 13385 13301 13286 13280>,
			<13346 13682 13401 13301 13286 13281>,
			<13343 13705 13420 13301 13286 13282>,
			<13342 13731 13441 13302 13286 13282>,
			<13341 13761 13462 13303 13285 13281>,
			<13340 13794 13487 13305 13284 13280>,
			<13339 13827 13518 13304 13284 13280>,
			<13336 13862 13554 13302 13284 13280>,
			<13333 13894 13592 13302 13285 13281>,
			<13331 13921 13633 13305 13286 13283>,
			<13329 13956 13678 13307 13286 13284>,
			<13324 14011 13727 13306 13286 13282>,
			<13315 14061 13775 13308 13285 13278>,
			<13313 14052 13782 13308 13287 13284>,
			<13316 14116 13843 13310 13290 13289>,
			<13327 14165 13883 13313 13294 13291>,
			<13334 14227 13962 13324 13297 13292>,
			<13339 14299 14005 13332 13298 13291>,
			<13338 14378 14075 13330 13294 13286>,
			<13337 14482 14142 13339 13294 13287>,
			<13351 14643 14262 13335 13299 13293>,
			<13373 15098 14404 13380 13307 13301>,
			<13373 15098 14404 13380 13307 13301>,
			<13373 15098 14404 13380 13307 13301>;
	};

	qcom,pc-temp-y4-lut {
		qcom,lut-col-legend = <(-10) 0 10 25 40 50>;
		qcom,lut-row-legend = <10000 9800 9600 9400 9200 9000>,
			<8800 8600 8400 8200 8000 7800>,
			<7600 7400 7200 7000 6800 6600>,
			<6400 6200 6000 5800 5600 5400>,
			<5200 5000 4800 4600 4400 4200>,
			<4000 3800 3600 3400 3200 3000>,
			<2800 2600 2400 2200 2000 1800>,
			<1600 1400 1200 1000 900 800>,
			<700 600 500 400 300 200>,
			<100 0>;
		qcom,lut-data = <16841 16816 16604 16499 16461 16453>,
			<16876 16850 16680 16502 16461 16454>,
			<16924 16888 16747 16508 16461 16454>,
			<16972 16924 16799 16515 16461 16454>,
			<17010 16950 16833 16520 16461 16455>,
			<17025 16960 16844 16523 16461 16455>,
			<17019 16953 16831 16523 16461 16455>,
			<17011 16943 16806 16523 16462 16456>,
			<17023 16949 16777 16524 16464 16457>,
			<17084 16988 16739 16526 16466 16459>,
			<17124 17035 16724 16528 16470 16461>,
			<17129 17096 16819 16532 16472 16463>,
			<17131 17149 16937 16539 16476 16465>,
			<17095 17111 16930 16548 16480 16469>,
			<16930 16931 16855 16562 16485 16475>,
			<16824 16817 16805 16578 16493 16481>,
			<16813 16794 16788 16596 16502 16488>,
			<16806 16779 16775 16615 16514 16497>,
			<16794 16761 16752 16634 16534 16513>,
			<16778 16742 16720 16652 16565 16536>,
			<16765 16721 16690 16658 16579 16545>,
			<16759 16691 16662 16596 16541 16519>,
			<16754 16665 16638 16516 16489 16486>,
			<16747 16656 16617 16490 16467 16468>,
			<16738 16651 16600 16477 16453 16454>,
			<16728 16648 16596 16473 16449 16450>,
			<16711 16646 16608 16473 16450 16451>,
			<16692 16644 16619 16473 16452 16452>,
			<16676 16645 16613 16473 16456 16454>,
			<16662 16650 16600 16473 16462 16460>,
			<16649 16653 16596 16474 16468 16467>,
			<16637 16655 16600 16475 16477 16477>,
			<16625 16656 16604 16476 16484 16485>,
			<16607 16659 16605 16479 16485 16489>,
			<16582 16664 16606 16484 16484 16491>,
			<16572 16669 16608 16488 16482 16489>,
			<16574 16675 16613 16491 16468 16469>,
			<16576 16680 16617 16494 16456 16452>,
			<16574 16681 16621 16494 16456 16452>,
			<16566 16682 16625 16495 16457 16455>,
			<16557 16682 16625 16496 16460 16459>,
			<16544 16676 16624 16500 16467 16467>,
			<16532 16670 16623 16506 16469 16466>,
			<16520 16664 16622 16514 16463 16452>,
			<16524 16668 16611 16511 16460 16448>,
			<16518 16670 16610 16510 16461 16457>,
			<16523 16683 16613 16522 16473 16478>,
			<16526 16708 16633 16538 16493 16509>,
			<16551 16738 16653 16551 16530 16542>,
			<16572 16765 16688 16578 16538 16534>,
			<16565 16763 16696 16571 16497 16468>,
			<16545 16757 16677 16568 16480 16470>,
			<16556 16769 16682 16635 16492 16480>,
			<16603 16926 16731 16643 16528 16513>,
			<16603 16926 16731 16643 16528 16513>,
			<16603 16926 16731 16643 16528 16513>;
	};

	qcom,pc-temp-y5-lut {
		qcom,lut-col-legend = <(-10) 0 10 25 40 50>;
		qcom,lut-row-legend = <10000 9800 9600 9400 9200 9000>,
			<8800 8600 8400 8200 8000 7800>,
			<7600 7400 7200 7000 6800 6600>,
			<6400 6200 6000 5800 5600 5400>,
			<5200 5000 4800 4600 4400 4200>,
			<4000 3800 3600 3400 3200 3000>,
			<2800 2600 2400 2200 2000 1800>,
			<1600 1400 1200 1000 900 800>,
			<700 600 500 400 300 200>,
			<100 0>;
		qcom,lut-data = <12131 11545 13641 18708 18528 22459>,
			<12310 11928 13412 19028 19067 22140>,
			<12522 12423 13309 19339 19513 21569>,
			<12762 12929 13310 19627 19850 20930>,
			<13027 13348 13396 19878 20063 20403>,
			<13316 13577 13548 20078 20135 20170>,
			<13718 13673 14103 20258 20063 20145>,
			<14081 13728 15080 20389 19883 20128>,
			<14037 13586 16388 20318 19465 19899>,
			<13559 12934 18314 19815 18410 19026>,
			<13285 12581 19156 19094 17609 18361>,
			<16528 14360 16950 17597 17291 18149>,
			<21170 16736 14201 16071 17071 17968>,
			<20875 16955 15348 16034 16909 17452>,
			<16184 16440 20364 16697 16793 16426>,
			<13456 15850 22632 17041 16648 15886>,
			<13539 15121 20605 16573 16345 15791>,
			<13673 14518 18023 15982 16065 15744>,
			<13744 14523 17161 16817 16088 15811>,
			<13792 14766 16720 20280 16382 16139>,
			<13808 14880 16226 22726 16935 16739>,
			<13414 14692 15568 23782 20112 19264>,
			<12890 14339 14937 24394 23612 21895>,
			<12842 13820 14490 24275 23979 22483>,
			<12961 13049 14128 23644 23976 22755>,
			<13074 12744 13628 23085 23942 22802>,
			<13161 12779 12693 22629 22867 22260>,
			<13228 12817 12010 22323 21334 21392>,
			<13253 12792 12254 22421 20356 20350>,
			<13263 12710 12871 22784 19542 19112>,
			<13283 12686 13055 22908 19308 18736>,
			<13430 12872 12962 22268 20129 18752>,
			<13748 13126 12884 21526 21324 18789>,
			<14616 13282 13018 21322 22262 19865>,
			<16750 13408 13342 21215 23149 22197>,
			<18514 13531 13582 21226 23382 22894>,
			<19754 13647 13747 21889 22432 22677>,
			<20573 13774 13908 22550 21279 22321>,
			<20645 13978 14115 21551 20829 21654>,
			<20636 14227 14316 18910 20554 20785>,
			<20616 14251 14394 18018 20207 20817>,
			<20457 13680 14424 18687 19652 22473>,
			<20053 13457 14293 18795 19456 22890>,
			<18034 13589 13820 17117 19479 21911>,
			<14880 13517 14093 16842 18229 17015>,
			<14687 13265 13433 16330 18269 19197>,
			<14982 13582 14021 15711 18871 19675>,
			<17187 13643 13610 15707 19224 18514>,
			<18688 13916 14344 18220 19068 17717>,
			<20137 14422 14177 19354 18803 17478>,
			<19623 14626 14478 17816 19559 18621>,
			<18624 14377 14350 16114 20583 18837>,
			<19101 14359 14282 14106 21589 21129>,
			<18727 13343 14015 15516 24775 25723>,
			<18727 13343 14015 15516 24775 25723>,
			<18727 13343 14015 15516 24775 25723>;
	};

	qcom,pc-temp-y6-lut {
		qcom,lut-col-legend = <(-10) 0 10 25 40 50>;
		qcom,lut-row-legend = <10000 9800 9600 9400 9200 9000>,
			<8800 8600 8400 8200 8000 7800>,
			<7600 7400 7200 7000 6800 6600>,
			<6400 6200 6000 5800 5600 5400>,
			<5200 5000 4800 4600 4400 4200>,
			<4000 3800 3600 3400 3200 3000>,
			<2800 2600 2400 2200 2000 1800>,
			<1600 1400 1200 1000 900 800>,
			<700 600 500 400 300 200>,
			<100 0>;
		qcom,lut-data = <6658 6315 5763 5193 5078 5056>,
			<6617 6272 5756 5194 5078 5056>,
			<6576 6231 5747 5194 5079 5057>,
			<6538 6192 5737 5194 5079 5057>,
			<6501 6155 5725 5194 5079 5058>,
			<6466 6122 5712 5193 5079 5058>,
			<6434 6090 5696 5192 5079 5058>,
			<6403 6061 5680 5191 5079 5059>,
			<6372 6034 5666 5189 5079 5059>,
			<6338 6005 5653 5187 5079 5059>,
			<6322 5993 5645 5186 5080 5060>,
			<6334 5997 5640 5186 5081 5061>,
			<6351 6001 5637 5185 5082 5062>,
			<6336 5987 5629 5186 5083 5063>,
			<6257 5925 5617 5190 5086 5064>,
			<6206 5881 5604 5194 5088 5066>,
			<6201 5868 5591 5199 5091 5068>,
			<6198 5859 5577 5205 5095 5072>,
			<6195 5853 5561 5210 5101 5077>,
			<6193 5847 5543 5214 5109 5084>,
			<6190 5841 5529 5215 5112 5086>,
			<6187 5830 5517 5194 5099 5076>,
			<6183 5820 5508 5168 5082 5064>,
			<6174 5819 5506 5160 5075 5057>,
			<6149 5821 5504 5157 5071 5053>,
			<6108 5824 5504 5156 5069 5052>,
			<5994 5833 5509 5157 5070 5052>,
			<5841 5847 5517 5158 5070 5053>,
			<5735 5860 5528 5160 5071 5054>,
			<5649 5873 5544 5163 5073 5055>,
			<5580 5889 5560 5166 5076 5057>,
			<5526 5909 5575 5168 5080 5060>,
			<5481 5932 5591 5171 5083 5063>,
			<5441 5953 5610 5176 5085 5065>,
			<5405 5973 5631 5181 5085 5067>,
			<5377 5996 5654 5187 5085 5067>,
			<5357 6021 5678 5192 5081 5061>,
			<5340 6048 5704 5197 5078 5056>,
			<5323 6074 5734 5201 5078 5056>,
			<5306 6100 5768 5205 5079 5058>,
			<5292 6127 5803 5211 5082 5060>,
			<5279 6151 5840 5223 5085 5064>,
			<5268 6182 5879 5235 5086 5065>,
			<5260 6225 5920 5246 5086 5060>,
			<5254 6274 5959 5258 5086 5058>,
			<5242 6273 5969 5261 5090 5065>,
			<5244 6329 6017 5273 5096 5075>,
			<5253 6374 6056 5288 5105 5085>,
			<5264 6431 6123 5310 5118 5095>,
			<5273 6499 6172 5333 5120 5092>,
			<5271 6567 6230 5338 5107 5071>,
			<5273 6652 6285 5355 5104 5073>,
			<5310 6797 6385 5405 5115 5082>,
			<5371 7235 6521 5472 5136 5100>,
			<5371 7235 6521 5472 5136 5100>,
			<5371 7235 6521 5472 5136 5100>;
	};

};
